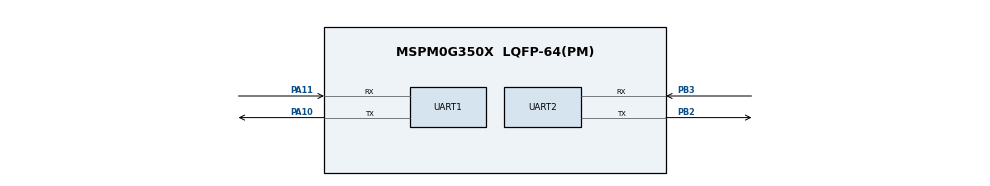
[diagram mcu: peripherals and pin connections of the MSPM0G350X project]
/**
 * @cliArgs --device "MSPM0G350X" --part "Default" --package "LQFP-64(PM)" --product "mspm0_sdk@2.02.00.05"
 * @versions {"tool":"1.21.1+3772"}
 */

/**
 * Import the modules used in this configuration.
 */
const SYSCTL  = scripting.addModule("/ti/driverlib/SYSCTL");
const SYSTICK = scripting.addModule("/ti/driverlib/SYSTICK");
const UART    = scripting.addModule("/ti/driverlib/UART", {}, false);
const UART1   = UART.addInstance();
const UART2   = UART.addInstance();

/**
 * Write custom configuration values to the imported modules.
 */
const divider6       = system.clockTree["PLL_CLK2X_DIV"];
divider6.divideValue = 4;

const divider7       = system.clockTree["PLL_PDIV"];
divider7.divideValue = 2;

const divider9       = system.clockTree["UDIV"];
divider9.divideValue = 2;

const gate7  = system.clockTree["MFCLKGATE"];
gate7.enable = true;

const multiplier2         = system.clockTree["PLL_QDIV"];
multiplier2.multiplyValue = 10;

const mux8       = system.clockTree["HSCLKMUX"];
mux8.inputSelect = "HSCLKMUX_SYSPLL2X";

SYSCTL.forceDefaultClkConfig = true;
SYSCTL.clockTreeEn           = true;

const Board = scripting.addModule("/ti/driverlib/Board", {}, false);

SYSTICK.periodEnable      = true;
SYSTICK.interruptEnable   = true;
SYSTICK.systickEnable     = true;
SYSTICK.period            = 80000;
SYSTICK.interruptPriority = "3";

UART1.$name                            = "user";
UART1.uartClkSrc                       = "MFCLK";
UART1.targetBaudRate                   = 115200;
UART1.peripheral.rxPin.$assign         = "PA11";
UART1.peripheral.txPin.$assign         = "PA10";
UART1.txPinConfig.$name                = "ti_driverlib_gpio_GPIOPinGeneric0";
UART1.txPinConfig.direction            = scripting.forceWrite("OUTPUT");
UART1.txPinConfig.hideOutputInversion  = scripting.forceWrite(false);
UART1.txPinConfig.onlyInternalResistor = scripting.forceWrite(false);
UART1.txPinConfig.passedPeripheralType = scripting.forceWrite("Digital");
UART1.rxPinConfig.$name                = "ti_driverlib_gpio_GPIOPinGeneric1";
UART1.rxPinConfig.hideOutputInversion  = scripting.forceWrite(false);
UART1.rxPinConfig.onlyInternalResistor = scripting.forceWrite(false);
UART1.rxPinConfig.passedPeripheralType = scripting.forceWrite("Digital");

UART2.$name                            = "MSPMotor";
UART2.targetBaudRate                   = 115200;
UART2.uartClkSrc                       = "MFCLK";
UART2.enabledInterrupts                = ["RX"];
UART2.interruptPriority                = "0";
UART2.peripheral.$assign               = "UART3";
UART2.peripheral.rxPin.$assign         = "PB3";
UART2.peripheral.txPin.$assign         = "PB2";
UART2.txPinConfig.$name                = "ti_driverlib_gpio_GPIOPinGeneric2";
UART2.txPinConfig.direction            = scripting.forceWrite("OUTPUT");
UART2.txPinConfig.hideOutputInversion  = scripting.forceWrite(false);
UART2.txPinConfig.onlyInternalResistor = scripting.forceWrite(false);
UART2.txPinConfig.passedPeripheralType = scripting.forceWrite("Digital");
UART2.rxPinConfig.$name                = "ti_driverlib_gpio_GPIOPinGeneric3";
UART2.rxPinConfig.hideOutputInversion  = scripting.forceWrite(false);
UART2.rxPinConfig.onlyInternalResistor = scripting.forceWrite(false);
UART2.rxPinConfig.passedPeripheralType = scripting.forceWrite("Digital");

/**
 * Pinmux solution for unlocked pins/peripherals. This ensures that minor changes to the automatic solver in a future
 * version of the tool will not impact the pinmux you originally saw.  These lines can be completely deleted in order to
 * re-solve from scratch.
 */
Board.peripheral.$suggestSolution          = "DEBUGSS";
Board.peripheral.swclkPin.$suggestSolution = "PA20";
Board.peripheral.swdioPin.$suggestSolution = "PA19";
UART1.peripheral.$suggestSolution          = "UART0";
